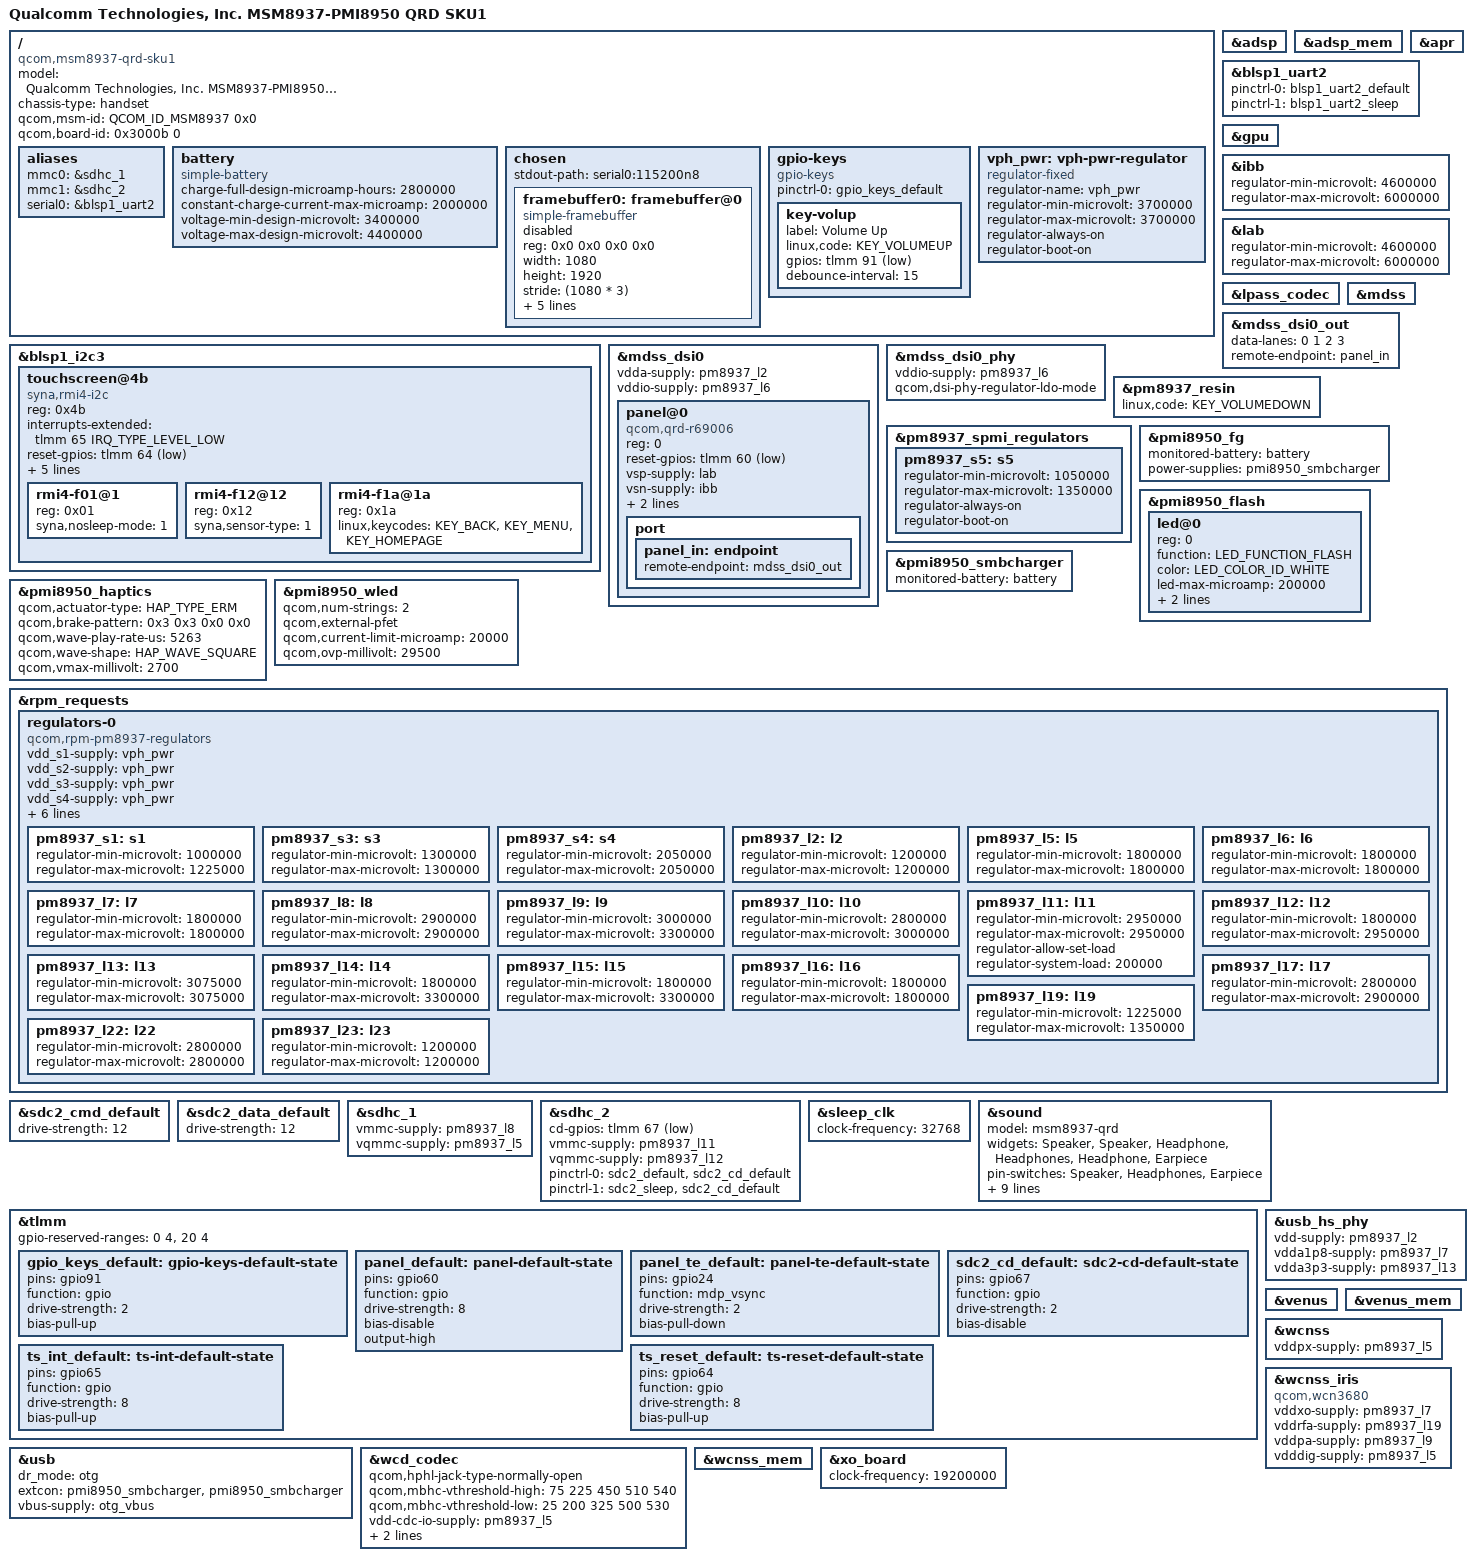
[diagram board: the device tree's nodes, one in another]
// SPDX-License-Identifier: BSD-3-Clause
/dts-v1/;

#include <dt-bindings/arm/qcom,ids.h>
#include <dt-bindings/gpio/gpio.h>
#include <dt-bindings/input/input.h>
#include <dt-bindings/leds/common.h>
#include <dt-bindings/interrupt-controller/irq.h>

#include "msm8937.dtsi"
#include "pm8937.dtsi"
#include "pmi8950.dtsi"
#include "msm8937-qdsp6.dtsi"

/ {
	model = "Qualcomm Technologies, Inc. MSM8937-PMI8950 QRD SKU1";
	compatible = "qcom,msm8937-qrd-sku1", "qcom,msm8937";
	chassis-type = "handset";

	qcom,msm-id = <QCOM_ID_MSM8937 0x0>;
	qcom,board-id = <0x3000b 0>;

	aliases {
		mmc0 = &sdhc_1;
		mmc1 = &sdhc_2;
		serial0 = &blsp1_uart2;
	};

	battery: battery {
		compatible = "simple-battery";

		charge-full-design-microamp-hours = <2800000>;
		constant-charge-current-max-microamp = <2000000>;
		voltage-min-design-microvolt = <3400000>;
		voltage-max-design-microvolt = <4400000>;
	};

	chosen {
		#address-cells = <2>;
		#size-cells = <2>;
		ranges;

		stdout-path = "serial0:115200n8";

		/* Address, size and format are filled in by lk2nd */
		framebuffer0: framebuffer@0 {
			compatible = "simple-framebuffer";
			reg = <0x0 0x0 0x0 0x0>;
			width = <1080>;
			height = <1920>;
			stride = <(1080 * 3)>;
			format = "r8g8b8";

			/*
			 * The byte, pixel and escape clocks are derived from the
			 * DSI PLL, which cannot be enabled before the DSI PHY
			 * driver sets it up. Leave them to the bootloader state.
			 */
			clocks = <&gcc GCC_MDSS_AHB_CLK>,
				 <&gcc GCC_MDSS_AXI_CLK>,
				 <&gcc GCC_MDSS_VSYNC_CLK>,
				 <&gcc GCC_MDSS_MDP_CLK>;
			power-domains = <&gcc MDSS_GDSC>;
			status = "disabled";
		};
	};

	gpio-keys {
		compatible = "gpio-keys";

		pinctrl-0 = <&gpio_keys_default>;
		pinctrl-names = "default";

		key-volup {
			label = "Volume Up";
			linux,code = <KEY_VOLUMEUP>;
			gpios = <&tlmm 91 GPIO_ACTIVE_LOW>;
			debounce-interval = <15>;
		};
	};

	vph_pwr: vph-pwr-regulator {
		compatible = "regulator-fixed";
		regulator-name = "vph_pwr";
		regulator-min-microvolt = <3700000>;
		regulator-max-microvolt = <3700000>;
		regulator-always-on;
		regulator-boot-on;
	};
};

&adsp {
	status = "okay";
};

&adsp_mem {
	status = "okay";
};

&apr {
	status = "okay";
};

&blsp1_i2c3 {
	status = "okay";

	touchscreen@4b {
		compatible = "syna,rmi4-i2c";
		reg = <0x4b>;
		#address-cells = <1>;
		#size-cells = <0>;

		interrupts-extended = <&tlmm 65 IRQ_TYPE_LEVEL_LOW>;
		reset-gpios = <&tlmm 64 GPIO_ACTIVE_LOW>;

		pinctrl-0 = <&ts_int_default>, <&ts_reset_default>;
		pinctrl-names = "default";

		vdd-supply = <&pm8937_l10>;
		vio-supply = <&pm8937_l6>;

		syna,reset-delay-ms = <200>;
		syna,startup-delay-ms = <200>;

		rmi4-f01@1 {
			reg = <0x01>;
			syna,nosleep-mode = <1>;
		};

		rmi4-f12@12 {
			reg = <0x12>;
			syna,sensor-type = <1>;
		};

		rmi4-f1a@1a {
			reg = <0x1a>;
			linux,keycodes = <KEY_BACK>, <KEY_MENU>, <KEY_HOMEPAGE>;
		};
	};
};

&blsp1_uart2 {
	pinctrl-0 = <&blsp1_uart2_default>;
	pinctrl-1 = <&blsp1_uart2_sleep>;
	pinctrl-names = "default", "sleep";

	status = "okay";
};

&gpu {
	status = "okay";
};

&ibb {
	regulator-min-microvolt = <4600000>;
	regulator-max-microvolt = <6000000>;
};

&lab {
	regulator-min-microvolt = <4600000>;
	regulator-max-microvolt = <6000000>;
};

&lpass_codec {
	status = "okay";
};

&mdss {
	status = "okay";
};

&mdss_dsi0 {
	vdda-supply = <&pm8937_l2>;
	vddio-supply = <&pm8937_l6>;

	status = "okay";

	panel@0 {
		compatible = "qcom,qrd-r69006";
		reg = <0>;

		reset-gpios = <&tlmm 60 GPIO_ACTIVE_LOW>;
		vsp-supply = <&lab>;
		vsn-supply = <&ibb>;
		backlight = <&pmi8950_wled>;

		pinctrl-0 = <&panel_default>, <&panel_te_default>;
		pinctrl-names = "default";

		port {
			panel_in: endpoint {
				remote-endpoint = <&mdss_dsi0_out>;
			};
		};
	};
};

&mdss_dsi0_out {
	data-lanes = <0 1 2 3>;
	remote-endpoint = <&panel_in>;
};

&mdss_dsi0_phy {
	vddio-supply = <&pm8937_l6>;
	qcom,dsi-phy-regulator-ldo-mode;

	status = "okay";
};

&pm8937_resin {
	linux,code = <KEY_VOLUMEDOWN>;

	status = "okay";
};

&pm8937_spmi_regulators {
	/* APC */
	pm8937_s5: s5 {
		regulator-min-microvolt = <1050000>;
		regulator-max-microvolt = <1350000>;
		regulator-always-on;
		regulator-boot-on;
	};
};

&pmi8950_fg {
	monitored-battery = <&battery>;
	power-supplies = <&pmi8950_smbcharger>;
	status = "okay";
};

&pmi8950_flash {
	#address-cells = <1>;
	#size-cells = <0>;
	status = "okay";

	led@0 {
		reg = <0>;
		function = LED_FUNCTION_FLASH;
		color = <LED_COLOR_ID_WHITE>;
		led-max-microamp = <200000>;
		flash-max-microamp = <1000000>;
		flash-max-timeout-us = <1280000>;
	};
};

&pmi8950_haptics {
	qcom,actuator-type = <HAP_TYPE_ERM>;
	qcom,brake-pattern = <0x3 0x3 0x0 0x0>;
	qcom,wave-play-rate-us = <5263>;
	qcom,wave-shape = <HAP_WAVE_SQUARE>;
	qcom,vmax-millivolt = <2700>;

	status = "okay";
};

&pmi8950_smbcharger {
	monitored-battery = <&battery>;
	status = "okay";
};

&pmi8950_wled {
	qcom,num-strings = <2>;
	qcom,external-pfet;
	qcom,current-limit-microamp = <20000>;
	qcom,ovp-millivolt = <29500>;

	status = "okay";
};

&rpm_requests {
	regulators-0 {
		compatible = "qcom,rpm-pm8937-regulators";

		vdd_s1-supply = <&vph_pwr>;
		vdd_s2-supply = <&vph_pwr>;
		vdd_s3-supply = <&vph_pwr>;
		vdd_s4-supply = <&vph_pwr>;

		vdd_l1_l19-supply = <&pm8937_s3>;
		vdd_l2_l23-supply = <&pm8937_s3>;
		vdd_l3-supply = <&pm8937_s3>;
		vdd_l4_l5_l6_l7_l16-supply = <&pm8937_s4>;
		vdd_l8_l11_l12_l17_l22-supply = <&vph_pwr>;
		vdd_l9_l10_l13_l14_l15_l18-supply = <&vph_pwr>;

		pm8937_s1: s1 {
			regulator-min-microvolt = <1000000>;
			regulator-max-microvolt = <1225000>;
		};

		pm8937_s3: s3 {
			regulator-min-microvolt = <1300000>;
			regulator-max-microvolt = <1300000>;
		};

		pm8937_s4: s4 {
			regulator-min-microvolt = <2050000>;
			regulator-max-microvolt = <2050000>;
		};

		pm8937_l2: l2 {
			regulator-min-microvolt = <1200000>;
			regulator-max-microvolt = <1200000>;
		};

		pm8937_l5: l5 {
			regulator-min-microvolt = <1800000>;
			regulator-max-microvolt = <1800000>;
		};

		pm8937_l6: l6 {
			regulator-min-microvolt = <1800000>;
			regulator-max-microvolt = <1800000>;
		};

		pm8937_l7: l7 {
			regulator-min-microvolt = <1800000>;
			regulator-max-microvolt = <1800000>;
		};

		pm8937_l8: l8 {
			regulator-min-microvolt = <2900000>;
			regulator-max-microvolt = <2900000>;
		};

		pm8937_l9: l9 {
			regulator-min-microvolt = <3000000>;
			regulator-max-microvolt = <3300000>;
		};

		pm8937_l10: l10 {
			regulator-min-microvolt = <2800000>;
			regulator-max-microvolt = <3000000>;
		};

		pm8937_l11: l11 {
			regulator-min-microvolt = <2950000>;
			regulator-max-microvolt = <2950000>;
			regulator-allow-set-load;
			regulator-system-load = <200000>;
		};

		pm8937_l12: l12 {
			regulator-min-microvolt = <1800000>;
			regulator-max-microvolt = <2950000>;
		};

		pm8937_l13: l13 {
			regulator-min-microvolt = <3075000>;
			regulator-max-microvolt = <3075000>;
		};

		pm8937_l14: l14 {
			regulator-min-microvolt = <1800000>;
			regulator-max-microvolt = <3300000>;
		};

		pm8937_l15: l15 {
			regulator-min-microvolt = <1800000>;
			regulator-max-microvolt = <3300000>;
		};

		pm8937_l16: l16 {
			regulator-min-microvolt = <1800000>;
			regulator-max-microvolt = <1800000>;
		};

		pm8937_l17: l17 {
			regulator-min-microvolt = <2800000>;
			regulator-max-microvolt = <2900000>;
		};

		pm8937_l19: l19 {
			regulator-min-microvolt = <1225000>;
			regulator-max-microvolt = <1350000>;
		};

		pm8937_l22: l22 {
			regulator-min-microvolt = <2800000>;
			regulator-max-microvolt = <2800000>;
		};

		pm8937_l23: l23 {
			regulator-min-microvolt = <1200000>;
			regulator-max-microvolt = <1200000>;
		};
	};
};

&sdc2_cmd_default {
	drive-strength = <12>;
};

&sdc2_data_default {
	drive-strength = <12>;
};

&sdhc_1 {
	vmmc-supply = <&pm8937_l8>;
	vqmmc-supply = <&pm8937_l5>;

	status = "okay";
};

&sdhc_2 {
	cd-gpios = <&tlmm 67 GPIO_ACTIVE_LOW>;
	vmmc-supply = <&pm8937_l11>;
	vqmmc-supply = <&pm8937_l12>;
	pinctrl-0 = <&sdc2_default &sdc2_cd_default>;
	pinctrl-1 = <&sdc2_sleep &sdc2_cd_default>;
	pinctrl-names = "default", "sleep";

	status = "okay";
};

&sleep_clk {
	clock-frequency = <32768>;
};

&sound {
	model = "msm8937-qrd";

	widgets =
		"Speaker", "Speaker",
		"Headphone", "Headphones",
		"Headphone", "Earpiece";
	pin-switches = "Speaker", "Headphones", "Earpiece";
	audio-routing =
		"Speaker", "SPK_OUT",
		"Earpiece", "EAR",
		"Headphones", "HPHL",
		"Headphones", "HPHR",
		"AMIC1", "MIC BIAS External1",
		"AMIC2", "MIC BIAS Internal2",
		"AMIC3", "MIC BIAS External1",
		"MM_DL1", "MultiMedia1 Playback",
		"MM_DL3", "MultiMedia3 Playback",
		"MM_DL4", "MultiMedia4 Playback",
		"MultiMedia2 Capture", "MM_UL2";

	status = "okay";
};

&tlmm {
	gpio-reserved-ranges = <0 4>, <20 4>;

	gpio_keys_default: gpio-keys-default-state {
		pins = "gpio91";
		function = "gpio";
		drive-strength = <2>;
		bias-pull-up;
	};

	panel_default: panel-default-state {
		pins = "gpio60";
		function = "gpio";
		drive-strength = <8>;
		bias-disable;
		output-high;
	};

	panel_te_default: panel-te-default-state {
		pins = "gpio24";
		function = "mdp_vsync";
		drive-strength = <2>;
		bias-pull-down;
	};

	sdc2_cd_default: sdc2-cd-default-state {
		pins = "gpio67";
		function = "gpio";
		drive-strength = <2>;
		bias-disable;
	};

	ts_int_default: ts-int-default-state {
		pins = "gpio65";
		function = "gpio";
		drive-strength = <8>;
		bias-pull-up;
	};

	ts_reset_default: ts-reset-default-state {
		pins = "gpio64";
		function = "gpio";
		drive-strength = <8>;
		bias-pull-up;
	};
};

&usb {
	dr_mode = "otg";
	extcon = <&pmi8950_smbcharger>, <&pmi8950_smbcharger>;
	vbus-supply = <&otg_vbus>;
	status = "okay";
};

&usb_hs_phy {
	vdd-supply = <&pm8937_l2>;
	vdda1p8-supply = <&pm8937_l7>;
	vdda3p3-supply = <&pm8937_l13>;
	status = "okay";
};

&venus {
	status = "okay";
};

&venus_mem {
	status = "okay";
};

&wcd_codec {
	qcom,hphl-jack-type-normally-open;
	qcom,mbhc-vthreshold-high = <75 225 450 510 540>;
	qcom,mbhc-vthreshold-low = <25 200 325 500 530>;

	vdd-cdc-io-supply = <&pm8937_l5>;
	vdd-cdc-tx-rx-cx-supply = <&pm8937_s4>;
	vdd-micbias-supply = <&pm8937_l13>;
	status = "okay";
};

&wcnss {
	vddpx-supply = <&pm8937_l5>;

	status = "okay";
};

&wcnss_iris {
	compatible = "qcom,wcn3680";
	vddxo-supply = <&pm8937_l7>;
	vddrfa-supply = <&pm8937_l19>;
	vddpa-supply = <&pm8937_l9>;
	vdddig-supply = <&pm8937_l5>;
};

&wcnss_mem {
	status = "okay";
};

&xo_board {
	clock-frequency = <19200000>;
};
